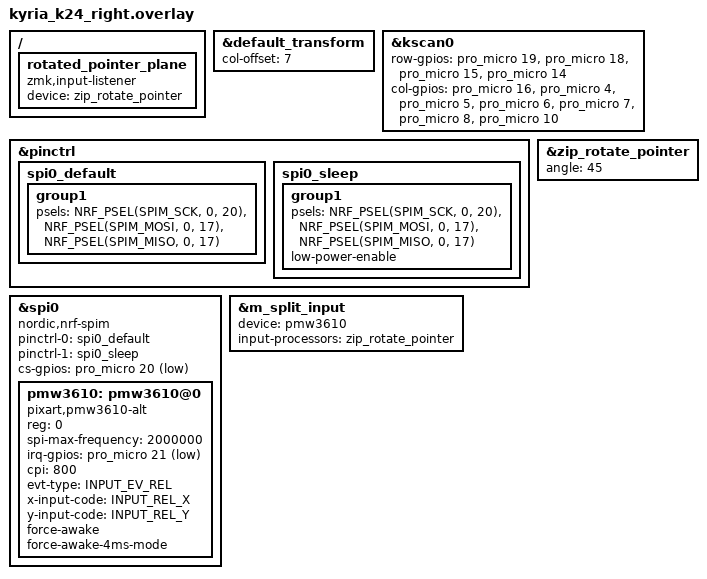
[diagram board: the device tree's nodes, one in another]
/*
 * Copyright (c) 2023 The ZMK Contributors
 *
 * SPDX-License-Identifier: MIT
 */

#include "kyria_k24.dtsi"
#include <input/processors/rotate_plane.dtsi>


#define INPUT_EV_KEY 0x01               /**< Key event */
#define INPUT_EV_REL 0x02               /**< Relative coordinate event */
#define INPUT_EV_ABS 0x03               /**< Absolute coordinate event */
#define INPUT_EV_MSC 0x04               /**< Miscellaneous event */
#define INPUT_EV_VENDOR_START 0xf0      /**< Vendor specific event start */
#define INPUT_EV_VENDOR_STOP 0xff       /**< Vendor specific event stop */

#define INPUT_REL_X 0x00                /**< Relative X coordinate */
#define INPUT_REL_Y 0x01                /**< Relative Y coordinate */
#define INPUT_REL_WHEEL 0x08            /**< Relative wheel coordinate */
#define INPUT_REL_HWHEEL 0x06           /**< Relative horizontal wheel coordinate */
#define INPUT_REL_MISC 0x09             /**< Relative misc coordinate */

&default_transform {
    col-offset = <7>;
};

&kscan0 {
    row-gpios
    = <&pro_micro 19 (GPIO_ACTIVE_HIGH | GPIO_PULL_DOWN)>
    , <&pro_micro 18 (GPIO_ACTIVE_HIGH | GPIO_PULL_DOWN)>
    , <&pro_micro 15 (GPIO_ACTIVE_HIGH | GPIO_PULL_DOWN)>
    , <&pro_micro 14 (GPIO_ACTIVE_HIGH | GPIO_PULL_DOWN)>
    ;
    col-gpios
    = <&pro_micro 16 GPIO_ACTIVE_HIGH>
    , <&pro_micro 4  GPIO_ACTIVE_HIGH>
    , <&pro_micro 5  GPIO_ACTIVE_HIGH>
    , <&pro_micro 6  GPIO_ACTIVE_HIGH>
    , <&pro_micro 7  GPIO_ACTIVE_HIGH>
    , <&pro_micro 8  GPIO_ACTIVE_HIGH>
    , <&pro_micro 10 GPIO_ACTIVE_HIGH>
    ;
};


&pinctrl {
    spi0_default: spi0_default {
        group1 {
            psels = <NRF_PSEL(SPIM_SCK, 0, 20)>,
                <NRF_PSEL(SPIM_MOSI, 0, 17)>,
                <NRF_PSEL(SPIM_MISO, 0, 17)>;
        };
    };

    spi0_sleep: spi0_sleep {
        group1 {
            psels = <NRF_PSEL(SPIM_SCK, 0, 20)>,
                <NRF_PSEL(SPIM_MOSI, 0, 17)>,
                <NRF_PSEL(SPIM_MISO, 0, 17)>;
            low-power-enable;
        };
    };
};

#include <zephyr/dt-bindings/input/input-event-codes.h>


&spi0 {
    status = "okay";
    compatible = "nordic,nrf-spim";
    pinctrl-0 = <&spi0_default>;
    pinctrl-1 = <&spi0_sleep>;
    pinctrl-names = "default", "sleep";
    cs-gpios = <&pro_micro 20 GPIO_ACTIVE_LOW>;

    pmw3610: pmw3610@0 {
        status = "okay";
        compatible = "pixart,pmw3610-alt";
        reg = <0>;
        spi-max-frequency = <2000000>;
        irq-gpios = <&pro_micro 21 (GPIO_ACTIVE_LOW  | GPIO_PULL_UP)>;
        cpi = <800>;
        evt-type = <INPUT_EV_REL>;
        x-input-code = <INPUT_REL_X>;
        y-input-code = <INPUT_REL_Y>;

       force-awake;
       force-awake-4ms-mode;
    };
};

&zip_rotate_pointer {
    angle = <45>;
};

&m_split_input {
    device = <&pmw3610>; /* only on the right side! */
    input-processors = <&zip_rotate_pointer>;
};

/ {
    rotated_pointer_plane {
        compatible = "zmk,input-listener";
        device = <&zip_rotate_pointer>;
    };
}
